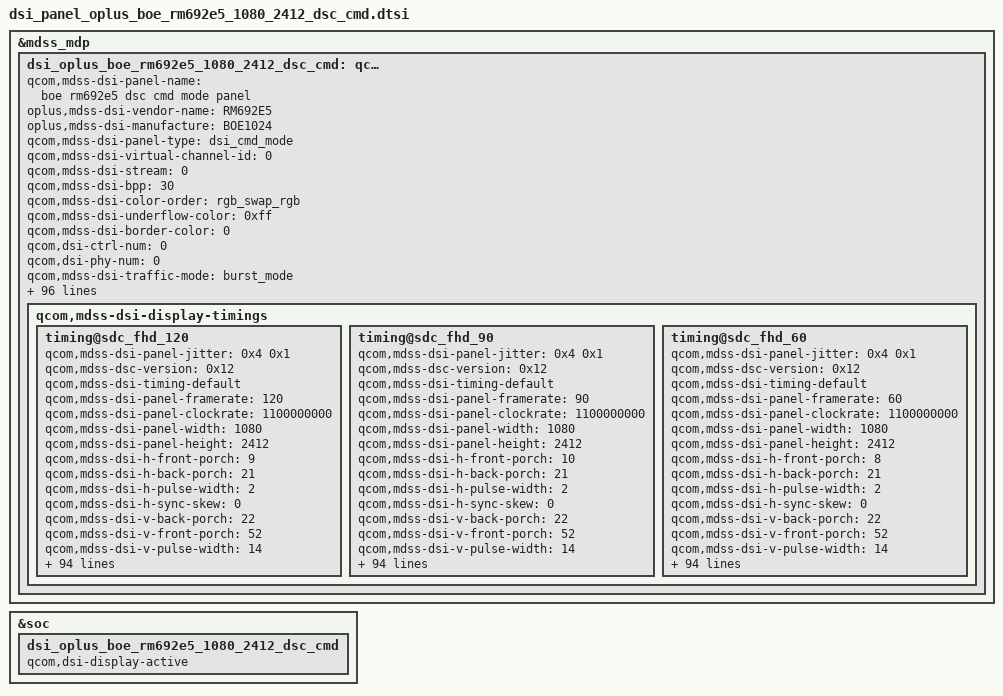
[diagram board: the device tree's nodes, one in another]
&mdss_mdp {
	dsi_oplus_boe_rm692e5_1080_2412_dsc_cmd: qcom,mdss_dsi_oplus_boe_rm692e5_1080_2412_dsc_cmd {
		qcom,mdss-dsi-panel-name = "boe rm692e5 dsc cmd mode panel";
		oplus,mdss-dsi-vendor-name = "RM692E5";
		oplus,mdss-dsi-manufacture = "BOE1024";
		qcom,mdss-dsi-panel-type = "dsi_cmd_mode";
		qcom,mdss-dsi-virtual-channel-id = <0>;
		qcom,mdss-dsi-stream = <0>;
		qcom,mdss-dsi-bpp = <30>;
		qcom,mdss-dsi-color-order = "rgb_swap_rgb";
		qcom,mdss-dsi-underflow-color = <0xff>;
		qcom,mdss-dsi-border-color = <0>;
		qcom,dsi-ctrl-num = <0>;
		qcom,dsi-phy-num = <0>;
		qcom,mdss-dsi-traffic-mode = "burst_mode";
		qcom,mdss-dsi-lane-map = "lane_map_0123";
		qcom,mdss-dsi-bllp-eof-power-mode;
		qcom,mdss-dsi-bllp-power-mode;
		qcom,mdss-dsi-lane-0-state;
		qcom,mdss-dsi-lane-1-state;
		qcom,mdss-dsi-lane-2-state;
		qcom,mdss-dsi-lane-3-state;
		qcom,mdss-dsi-dma-trigger = "trigger_sw";
		qcom,mdss-loading-effect;
		qcom,mdss-dsi-mdp-trigger = "none";
		qcom,mdss-dsi-reset-sequence = <1 10>, <0 5>, <1 32>;
		qcom,mdss-dsi-te-pin-select = <1>;
		qcom,mdss-dsi-te-dcs-command = <1>;
		qcom,mdss-pan-physical-width-dimension = <70>;
		qcom,mdss-pan-physical-height-dimension = <155>;
		qcom,mdss-dsi-init-delay-us = <1000>;
		qcom,mdss-dsi-te-check-enable;
		qcom,mdss-dsi-te-using-te-pin;
		qcom,mdss-dsi-lp11-init;
		qcom,mdss-dsi-wr-mem-start = <0x2c>;
		qcom,mdss-dsi-wr-mem-continue = <0x3c>;
		qcom,mdss-dsi-panel-jitter = <0x4 0x1>;
		//qcom,mdss-dsc-scr-version = <0x1>;
		qcom,mdss-bl-high2bit;
		/* HDR Setting */
		qcom,mdss-dsi-panel-hdr-enabled;
		qcom,mdss-dsi-panel-hdr-color-primaries = <15635 16450 34000 16000 13250 34500 7500 3000>;
		qcom,mdss-dsi-panel-peak-brightness = <5400000>;
		qcom,mdss-dsi-panel-average-brightness = <2000000>;
		qcom,mdss-dsi-panel-blackness-level = <4000>;

		qcom,mdss-dsi-te-using-wd;
		//qcom,esd-check-enabled;
		qcom,mdss-dsi-panel-status-check-mode = "reg_read";
		qcom,mdss-dsi-panel-status-command = [
			06 01 00 00 00 00 02 0B 00
			06 01 00 00 00 00 02 0A 00
			06 01 00 00 00 00 02 FA 00
		];
		qcom,mdss-dsi-panel-status-command-state = "dsi_lp_mode";
		qcom,mdss-dsi-panel-status-value = <0x00 0x9C 0x01>;
		qcom,mdss-dsi-panel-status-read-length = <1 1 1>;
		oplus,mdss-dsi-panel-status-match-modes = <0x00000000>;

		qcom,dynamic-mode-switch-enabled;
		qcom,dynamic-mode-switch-type = "dynamic-resolution-switch-immediate";
		qcom,mdss-dsi-display-timings {
			timing@sdc_fhd_120{
				//qcom,mdss-mdp-transfer-time-us = <12000>;
				qcom,mdss-dsi-panel-jitter = <0x4 0x1>;
				//qcom,mdss-dsc-scr-version = <0x1>;
				qcom,mdss-dsc-version = <0x12>;
				qcom,mdss-dsi-timing-default;
				qcom,mdss-dsi-panel-framerate = <120>;
				qcom,mdss-dsi-panel-clockrate = <1100000000>;
				//qcom,mdss-dsi-panel-clockrate = <900000000>;
				qcom,mdss-dsi-panel-width = <1080>;
				qcom,mdss-dsi-panel-height = <2412>;

				qcom,mdss-dsi-h-front-porch = <9>;
				qcom,mdss-dsi-h-back-porch = <21>;
				qcom,mdss-dsi-h-pulse-width = <2>;
				qcom,mdss-dsi-h-sync-skew = <0>;
				qcom,mdss-dsi-v-back-porch = <22>;
				qcom,mdss-dsi-v-front-porch = <52>;
				qcom,mdss-dsi-v-pulse-width = <14>;
				qcom,mdss-dsi-h-sync-pulse = <0>;

				qcom,mdss-dsi-h-left-border = <0>;
				qcom,mdss-dsi-h-right-border = <0>;
				qcom,mdss-dsi-v-top-border = <0>;
				qcom,mdss-dsi-v-bottom-border = <0>;

				oplus,ofp-aod-off-insert-black = <2>;

				/* Apollo vsync config, need to measure TE signal */
				//oplus,apollo-panel-vsync-width = <13000>;
				//oplus,apollo-panel-vsync-period = <16600>;

				/* ofp config */
				oplus,ofp-need-to-separate-backlight;
				oplus,ofp-hbm-on-period = <2>;

				qcom,mdss-dsi-panel-read-register-open-command = [
					39 01 00 00 00 00 03 F0 5A 5A
					];
				qcom,mdss-dsi-panel-id1-command = [
					06 01 00 00 00 00 01 E9
					];
				qcom,mdss-dsi-panel-read-register-close-command = [
					39 01 00 00 00 00 03 F0 A5 A5
					];
				qcom,mdss-dsi-timing-switch-command = [
					15 01 00 00 00 00 02 FE 40
					15 01 00 00 00 00 02 BD 05
					15 01 00 00 00 00 02 FE 00
					];
				qcom,mdss-dsi-on-command=[
					15 01 00 00 00 00 02 FE F4
					15 01 00 00 00 00 02 00 FF
					15 01 00 00 00 00 02 01 B3
					15 01 00 00 00 00 02 02 CC
					15 01 00 00 00 00 02 03 29
					15 01 00 00 00 00 02 04 74
					15 01 00 00 00 00 02 05 72
					15 01 00 00 00 00 02 06 DD
					15 01 00 00 00 00 02 07 25
					15 01 00 00 00 00 02 08 18
					15 01 00 00 00 00 02 09 61
					15 01 00 00 00 00 02 0A 35
					15 01 00 00 00 00 02 0B 01
					15 01 00 00 00 00 02 0C F4
					15 01 00 00 00 00 02 0D 0C

					15 01 00 00 00 00 02 FE F4
					15 01 00 00 00 00 02 1B F0
					15 01 00 00 00 00 02 1C 7F
					15 01 00 00 00 00 02 1D DE
					15 01 00 00 00 00 02 1E 13
					15 01 00 00 00 00 02 1F 13
					15 01 00 00 00 00 02 20 2A
					15 01 00 00 00 00 02 21 D7
					15 01 00 00 00 00 02 22 5D
					15 01 00 00 00 00 02 23 82
					15 01 00 00 00 00 02 24 11
					15 01 00 00 00 00 02 25 56
					15 01 00 00 00 00 02 26 13
					15 01 00 00 00 00 02 27 40
					15 01 00 00 00 00 02 28 CF
					15 01 00 00 00 00 02 29 00

					15 01 00 00 00 00 02 FE F4
					15 01 00 00 00 00 02 0D C0
					15 01 00 00 00 00 02 0E FF
					15 01 00 00 00 00 02 0F F9
					15 01 00 00 00 00 02 10 0B
					15 01 00 00 00 00 02 11 5E
					15 01 00 00 00 00 02 12 B2
					15 01 00 00 00 00 02 13 5C
					15 01 00 00 00 00 02 14 77
					15 01 00 00 00 00 02 15 09
					15 01 00 00 00 00 02 16 46
					15 01 00 00 00 00 02 17 58
					15 01 00 00 00 00 02 18 4D
					15 01 00 00 00 00 02 19 00
					15 01 00 00 00 00 02 1A 3D
					15 01 00 00 00 00 02 1B 03

					15 01 00 00 00 00 02 FE D2
					15 01 00 00 00 00 02 50 12
					15 01 00 00 00 00 02 51 a0
					15 01 00 00 00 00 02 52 30
					15 01 00 00 00 00 02 53 09
					15 01 00 00 00 00 02 54 6c
					15 01 00 00 00 00 02 55 04
					15 01 00 00 00 00 02 56 38
					15 01 00 00 00 00 02 58 00
					15 01 00 00 00 00 02 59 0c
					15 01 00 00 00 00 02 5a 02
					15 01 00 00 00 00 02 5b 1c
					15 01 00 00 00 00 02 5c 01
					15 01 00 00 00 00 02 5d 9a
					15 01 00 00 00 00 02 5e 19
					15 01 00 00 00 00 02 5f 01
					15 01 00 00 00 00 02 60 03
					15 01 00 00 00 00 02 61 00
					15 01 00 00 00 00 02 62 0a
					15 01 00 00 00 00 02 63 0c
					15 01 00 00 00 00 02 64 08
					15 01 00 00 00 00 02 65 bb
					15 01 00 00 00 00 02 66 0a
					15 01 00 00 00 00 02 67 5f
					15 01 00 00 00 00 02 68 16
					15 01 00 00 00 00 02 69 00
					15 01 00 00 00 00 02 6a 10
					15 01 00 00 00 00 02 6b ec
					15 01 00 00 00 00 02 6c 07
					15 01 00 00 00 00 02 6d 10
					15 01 00 00 00 00 02 6e 20
					15 01 00 00 00 00 02 6f 00
					15 01 00 00 00 00 02 70 06
					15 01 00 00 00 00 02 71 0f
					15 01 00 00 00 00 02 72 0f
					15 01 00 00 00 00 02 73 33
					15 01 00 00 00 00 02 74 0e
					15 01 00 00 00 00 02 75 1c
					15 01 00 00 00 00 02 76 2a
					15 01 00 00 00 00 02 77 38
					15 01 00 00 00 00 02 78 46
					15 01 00 00 00 00 02 79 54
					15 01 00 00 00 00 02 7a 62
					15 01 00 00 00 00 02 7b 69
					15 01 00 00 00 00 02 7c 70
					15 01 00 00 00 00 02 7d 77
					15 01 00 00 00 00 02 7e 79
					15 01 00 00 00 00 02 7f 7b
					15 01 00 00 00 00 02 80 7d
					15 01 00 00 00 00 02 81 7e
					15 01 00 00 00 00 02 82 01
					15 01 00 00 00 00 02 83 c2
					15 01 00 00 00 00 02 84 22
					15 01 00 00 00 00 02 85 00
					15 01 00 00 00 00 02 86 2a
					15 01 00 00 00 00 02 87 40
					15 01 00 00 00 00 02 88 32
					15 01 00 00 00 00 02 89 be
					15 01 00 00 00 00 02 8a 3a
					15 01 00 00 00 00 02 8b fc
					15 01 00 00 00 00 02 8c 3a
					15 01 00 00 00 00 02 8d fa
					15 01 00 00 00 00 02 8e 3a
					15 01 00 00 00 00 02 8f f8
					15 01 00 00 00 00 02 90 3b
					15 01 00 00 00 00 02 91 38
					15 01 00 00 00 00 02 92 3b
					15 01 00 00 00 00 02 93 78
					15 01 00 00 00 00 02 94 3b
					15 01 00 00 00 00 02 95 76
					15 01 00 00 00 00 02 96 4b
					15 01 00 00 00 00 02 97 b6
					15 01 00 00 00 00 02 98 4b
					15 01 00 00 00 00 02 99 b6
					15 01 00 00 00 00 02 9a 4b
					15 01 00 00 00 00 02 9b f4
					15 01 00 00 00 00 02 9c 5b
					15 01 00 00 00 00 02 9d f4
					15 01 00 00 00 00 02 9e 7c
					15 01 00 00 00 00 02 9f 34
					15 01 00 00 00 00 02 a2 02
					15 01 00 00 00 00 02 a3 a3
					15 01 00 00 00 00 02 a4 00
					15 01 00 00 00 00 02 a5 00
					15 01 00 00 00 00 02 a6 00
					15 01 00 00 00 00 02 a7 00
					15 01 00 00 00 00 02 a9 00
					15 01 00 00 00 00 02 aa 00
					15 01 00 00 00 00 02 a0 a0

					15 01 00 00 00 00 02 FE D4
					15 01 00 00 00 00 02 40 03
					15 01 00 00 00 00 02 FE FD
					15 01 00 00 00 00 02 80 06
					15 01 00 00 00 00 02 83 00
					15 01 00 00 00 00 02 FE A0
					15 01 00 00 00 00 02 06 36
					15 01 00 00 00 00 02 FE A1
					15 01 00 00 00 00 02 B3 7F
					15 01 00 00 00 00 02 74 70
					15 01 00 00 00 00 02 FE A1
					15 01 00 00 00 00 02 C3 C3
					15 01 00 00 00 00 02 C4 9C
					15 01 00 00 00 00 02 C5 1E
					15 01 00 00 00 00 02 C6 23

					15 01 00 00 00 00 02 FE 38
					15 01 00 00 00 00 02 18 13
					15 01 00 00 00 00 02 FE 40
					15 01 00 00 00 00 02 BD 05
					15 01 00 00 00 00 02 FE D0
					15 01 00 00 00 00 02 86 14
					15 01 00 00 00 00 02 FE A1
					15 01 00 00 00 00 02 CA 80

					15 01 00 00 00 00 02 FE A1
					15 01 00 00 00 00 02 B3 1F

					/* Setting AOD Black Frames */
					15 01 00 00 00 00 02 FE 40
					15 01 00 00 00 00 02 84 22

					15 01 00 00 00 00 02 FE 00
					15 01 00 00 00 00 02 FA 01
					15 01 00 00 00 00 02 C2 08
					15 01 00 00 00 00 02 35 00

					05 01 00 00 64 00 01 11
					05 01 00 00 0A 00 01 29
				];
				qcom,mdss-dsi-post-on-backlight = [
					/* Display On */
					//05 01 00 00 00 00 02 29 00
				];
				qcom,mdss-dsi-off-command=[
					15 00 00 00 00 00 02 FE 00
					05 00 00 00 0A 00 01 28
					05 00 00 00 64 00 01 10
				];
				qcom,mdss-dsi-lp1-command = [
					/* AOD 50 nit */
					15 00 00 40 00 00 02 FE 74
					15 00 00 40 00 00 02 EC 77
					15 00 00 40 00 00 02 ED 77
					15 00 00 40 00 00 02 EF FF
					15 00 00 40 00 00 02 F0 FF
					15 00 00 40 00 00 02 F2 FF
					15 00 00 00 09 00 02 F3 FF
					/* AOD ON */
					15 00 00 40 00 00 02 FE 40
					15 00 00 40 00 00 02 84 22
					15 00 00 40 00 00 02 B3 50
					15 00 00 40 00 00 02 FE 00
					05 00 00 40 00 00 01 39
					39 00 00 00 11 00 03 51 0F FE
				];
				qcom,mdss-dsi-nolp-command = [
					/* AOD OFF */
					15 00 00 40 00 00 02 FE 40
					15 00 00 40 00 00 02 84 24
					15 00 00 40 00 00 02 B3 4F
					15 00 00 40 00 00 02 FE 00
					05 00 00 00 11 00 01 38
				];
				qcom,mdss-dsi-aod-hbm-on-command = [
					/* AOD OFF */
					15 00 00 40 00 00 02 FE 40
					15 00 00 40 00 00 02 84 22
					15 00 00 40 00 00 02 B3 4F
					15 00 00 40 00 00 02 FE 00
					05 00 00 00 44 00 01 38
					/* HBM ON */
					15 00 00 40 00 00 02 FE 00
					39 00 00 00 00 00 03 51 0F FF
				];
				qcom,mdss-dsi-aod-hbm-off-command = [
					/* HBM OFF */
					15 00 00 40 00 00 02 FE 00
					39 00 00 00 00 00 03 51 00 00
					/* AOD 50 nit */
					15 00 00 40 00 00 02 FE 74
					15 00 00 40 00 00 02 EC 77
					15 00 00 40 00 00 02 ED 77
					15 00 00 40 00 00 02 EF FF
					15 00 00 40 00 00 02 F0 FF
					15 00 00 40 00 00 02 F2 FF
					15 00 00 00 09 00 02 F3 FF
					/* AOD ON */
					15 00 00 40 00 00 02 FE 40
					15 00 00 40 00 00 02 84 22
					15 00 00 40 00 00 02 B3 50
					15 00 00 40 00 00 02 FE 00
					05 00 00 40 00 00 01 39
					39 00 00 00 11 00 03 51 0F FE
				];
				qcom,mdss-dsi-hbm-off-command = [
					15 00 00 00 22 00 02 53 E0
					39 00 00 00 0A 00 03 51 00 4B
				];
				qcom,mdss-dsi-hbm-on-command = [
					/* HBM ON */
					15 00 00 40 00 00 02 FE 00
					39 00 00 00 00 00 03 51 0F FF
				];
				qcom,mdss-dsi-hbm-enter-switch-command = [
					15 01 00 40 00 00 02 FE 00
					39 01 00 00 00 00 03 51 0F FF
				];
				qcom,mdss-dsi-hbm-exit-switch-command = [
					15 01 00 40 00 00 02 FE 00
					39 01 00 00 00 00 03 51 0D BB
				];
				qcom,mdss-dsi-aod-high-mode-command = [
					/* AOD 50 nit */
					15 00 00 40 00 00 02 FE 74
					15 00 00 40 00 00 02 EC 77
					15 00 00 40 00 00 02 ED 77
					15 00 00 40 00 00 02 EF FF
					15 00 00 40 00 00 02 F0 FF
					15 00 00 40 00 00 02 F2 FF
					15 00 00 00 09 00 02 F3 FF
				];
				qcom,mdss-dsi-aod-low-mode-command = [
					/* AOD 10 nit */
					15 00 00 40 00 00 02 FE 74
					15 00 00 40 00 00 02 EC 11
					15 00 00 40 00 00 02 ED 11
					15 00 00 40 00 00 02 EF 98
					15 00 00 40 00 00 02 F0 98
					15 00 00 40 00 00 02 F2 98
					15 00 00 00 09 00 02 F3 98
				];
				qcom,mdss-dsi-esd-switch-page-command = [
					15 01 00 00 00 00 02 FE 00
				];
				qcom,dsi-panel-date-switch-command = [
					15 01 00 00 00 00 02 FE D2
					15 01 00 00 00 00 02 0C 60

					15 01 00 00 00 00 02 FE 88
					15 01 00 00 00 00 02 19 81
					15 01 00 00 00 00 02 18 01
					15 01 00 00 00 00 02 1B 0F
					15 01 00 00 00 00 02 00 A1
					15 01 00 00 00 00 02 02 00
					15 01 00 00 00 00 02 03 C2

					15 01 00 00 00 00 02 FE 00
				];
				qcom,mdss-dsi-ffc-mode0-command = [
					/* CLK=550MHz, OSC=121.9MHz */
					15 00 00 40 00 00 02 FE D4
					15 00 00 40 00 00 02 14 00
					15 00 00 40 00 00 02 FE 40
					15 00 00 40 00 00 02 0A 9F
					15 00 00 40 00 00 02 0B 16
					15 00 00 40 00 00 02 0C 7E
					15 00 00 40 00 00 02 BE 9F
					15 00 00 00 00 00 02 C0 9F
				];
				qcom,mdss-dsi-ffc-mode1-command = [
					/* CLK=550MHz, OSC=121MHz */
					15 00 00 40 00 00 02 FE 40
					15 00 00 40 00 00 02 0A 9C
					15 00 00 40 00 00 02 0B 16
					15 00 00 40 00 00 02 0C 70
					15 00 00 40 00 00 02 BE 9C
					15 00 00 40 00 00 02 C0 9C
					15 00 00 00 00 00 02 16 04

					15 00 00 40 00 00 02 FE D4
					15 00 00 40 00 00 02 14 83
					15 00 00 40 00 00 02 1E 00
					15 00 00 40 00 00 02 1F 16
					15 00 00 40 00 00 02 20 21
					15 00 00 40 00 00 02 21 0C
					15 00 00 40 00 00 02 22 5D
					15 00 00 40 00 00 02 23 0A
					15 00 00 00 00 00 02 24 D1

					15 00 00 40 00 00 02 25 00
					15 00 00 40 00 00 02 26 16
					15 00 00 40 00 00 02 27 21
					15 00 00 40 00 00 02 28 0C
					15 00 00 40 00 00 02 29 5D
					15 00 00 40 00 00 02 2A 0A
					15 00 00 00 00 00 02 2B D1

					15 00 00 40 00 00 02 2D 00
					15 00 00 40 00 00 02 2F 16
					15 00 00 40 00 00 02 30 21
					15 00 00 40 00 00 02 31 0C
					15 00 00 40 00 00 02 32 5D
					15 00 00 40 00 00 02 33 0A
					15 00 00 00 00 00 02 34 D1
				];
				qcom,mdss-dsi-set-backlight-command = [
					15 00 00 40 00 00 02 FE 00
					39 00 00 00 00 00 03 51 06 66
				];
				qcom,mdss-dsi-set-backlight-command-state = "dsi_lp_mode";
				qcom,mdss-dsi-ffc-mode0-command-state = "dsi_lp_mode";
				qcom,mdss-dsi-ffc-mode1-command-state = "dsi_lp_mode";
				qcom,mdss-dsi-aod-hbm-on-command-state = "dsi_lp_mode";
				qcom,mdss-dsi-aod-hbm-off-command-state = "dsi_lp_mode";
				qcom,mdss-dsi-timing-switch-command-state = "dsi_lp_mode";
				qcom,mdss-dsi-on-command-state = "dsi_lp_mode";
				qcom,mdss-dsi-off-command-state = "dsi_lp_mode";
				qcom,mdss-dsi-hbm-on-command-state = "dsi_lp_mode";
				qcom,mdss-dsi-hbm-off-command-state = "dsi_lp_mode";
				qcom,mdss-dsi-nolp-command-state = "dsi_lp_mode";
				qcom,mdss-dsi-lp1-command-state = "dsi_lp_mode";
				qcom,mdss-dsi-aor-restore-command-state = "dsi_lp_mode";
				qcom,dsi-panel-date-switch-command-state = "dsi_lp_mode";

				qcom,lm-split = <540 540>;
				qcom,compression-mode = "dsc";
				qcom,mdss-dsc-encoders = <2>;
				qcom,mdss-dsc-slice-height = <12>;
				qcom,mdss-dsc-slice-width = <540>;
				qcom,mdss-dsc-slice-per-pkt = <1>;
				qcom,mdss-dsc-bit-per-component = <10>;
				qcom,mdss-dsc-bit-per-pixel = <10>;
				qcom,mdss-dsc-block-prediction-enable;
				qcom,mdss-dsi-panel-id1-command-state = "dsi_lp_mode";
				qcom,mdss-dsi-panel-read-register-open-state = "dsi_lp_mode";
				qcom,mdss-dsi-panel-read-register-close-state = "dsi_lp_mode";
			};
			timing@sdc_fhd_90{
				//qcom,mdss-mdp-transfer-time-us = <12000>;
				qcom,mdss-dsi-panel-jitter = <0x4 0x1>;
				//qcom,mdss-dsc-scr-version = <0x1>;
				qcom,mdss-dsc-version = <0x12>;
				qcom,mdss-dsi-timing-default;
				qcom,mdss-dsi-panel-framerate = <90>;
				qcom,mdss-dsi-panel-clockrate = <1100000000>;
				//qcom,mdss-dsi-panel-clockrate = <900000000>;
				qcom,mdss-dsi-panel-width = <1080>;
				qcom,mdss-dsi-panel-height = <2412>;

				qcom,mdss-dsi-h-front-porch = <10>;
				qcom,mdss-dsi-h-back-porch = <21>;
				qcom,mdss-dsi-h-pulse-width = <2>;
				qcom,mdss-dsi-h-sync-skew = <0>;
				qcom,mdss-dsi-v-back-porch = <22>;
				qcom,mdss-dsi-v-front-porch = <52>;
				qcom,mdss-dsi-v-pulse-width = <14>;
				qcom,mdss-dsi-h-sync-pulse = <0>;

				qcom,mdss-dsi-h-left-border = <0>;
				qcom,mdss-dsi-h-right-border = <0>;
				qcom,mdss-dsi-v-top-border = <0>;
				qcom,mdss-dsi-v-bottom-border = <0>;

				oplus,ofp-aod-off-insert-black = <2>;

				/* Apollo vsync config, need to measure TE signal */
				//oplus,apollo-panel-vsync-width = <13000>;
				//oplus,apollo-panel-vsync-period = <16600>;

				/* ofp config */
				oplus,ofp-need-to-separate-backlight;
				oplus,ofp-hbm-on-period = <2>;

				qcom,mdss-dsi-panel-read-register-open-command = [
					39 01 00 00 00 00 03 F0 5A 5A
					];
				qcom,mdss-dsi-panel-id1-command = [
					06 01 00 00 00 00 01 E9
					];
				qcom,mdss-dsi-panel-read-register-close-command = [
					39 01 00 00 00 00 03 F0 A5 A5
					];
				qcom,mdss-dsi-timing-switch-command = [
					15 01 00 00 00 00 02 FE 40
					15 01 00 00 00 00 02 BD 06
					15 01 00 00 00 00 02 FE 00
					];
				qcom,mdss-dsi-on-command=[
					15 01 00 00 00 00 02 FE F4
					15 01 00 00 00 00 02 00 FF
					15 01 00 00 00 00 02 01 B3
					15 01 00 00 00 00 02 02 CC
					15 01 00 00 00 00 02 03 29
					15 01 00 00 00 00 02 04 74
					15 01 00 00 00 00 02 05 72
					15 01 00 00 00 00 02 06 DD
					15 01 00 00 00 00 02 07 25
					15 01 00 00 00 00 02 08 18
					15 01 00 00 00 00 02 09 61
					15 01 00 00 00 00 02 0A 35
					15 01 00 00 00 00 02 0B 01
					15 01 00 00 00 00 02 0C F4
					15 01 00 00 00 00 02 0D 0C

					15 01 00 00 00 00 02 FE F4
					15 01 00 00 00 00 02 1B F0
					15 01 00 00 00 00 02 1C 7F
					15 01 00 00 00 00 02 1D DE
					15 01 00 00 00 00 02 1E 13
					15 01 00 00 00 00 02 1F 13
					15 01 00 00 00 00 02 20 2A
					15 01 00 00 00 00 02 21 D7
					15 01 00 00 00 00 02 22 5D
					15 01 00 00 00 00 02 23 82
					15 01 00 00 00 00 02 24 11
					15 01 00 00 00 00 02 25 56
					15 01 00 00 00 00 02 26 13
					15 01 00 00 00 00 02 27 40
					15 01 00 00 00 00 02 28 CF
					15 01 00 00 00 00 02 29 00

					15 01 00 00 00 00 02 FE F4
					15 01 00 00 00 00 02 0D C0
					15 01 00 00 00 00 02 0E FF
					15 01 00 00 00 00 02 0F F9
					15 01 00 00 00 00 02 10 0B
					15 01 00 00 00 00 02 11 5E
					15 01 00 00 00 00 02 12 B2
					15 01 00 00 00 00 02 13 5C
					15 01 00 00 00 00 02 14 77
					15 01 00 00 00 00 02 15 09
					15 01 00 00 00 00 02 16 46
					15 01 00 00 00 00 02 17 58
					15 01 00 00 00 00 02 18 4D
					15 01 00 00 00 00 02 19 00
					15 01 00 00 00 00 02 1A 3D
					15 01 00 00 00 00 02 1B 03

					15 01 00 00 00 00 02 FE D2
					15 01 00 00 00 00 02 50 12
					15 01 00 00 00 00 02 51 a0
					15 01 00 00 00 00 02 52 30
					15 01 00 00 00 00 02 53 09
					15 01 00 00 00 00 02 54 6c
					15 01 00 00 00 00 02 55 04
					15 01 00 00 00 00 02 56 38
					15 01 00 00 00 00 02 58 00
					15 01 00 00 00 00 02 59 0c
					15 01 00 00 00 00 02 5a 02
					15 01 00 00 00 00 02 5b 1c
					15 01 00 00 00 00 02 5c 01
					15 01 00 00 00 00 02 5d 9a
					15 01 00 00 00 00 02 5e 19
					15 01 00 00 00 00 02 5f 01
					15 01 00 00 00 00 02 60 03
					15 01 00 00 00 00 02 61 00
					15 01 00 00 00 00 02 62 0a
					15 01 00 00 00 00 02 63 0c
					15 01 00 00 00 00 02 64 08
					15 01 00 00 00 00 02 65 bb
					15 01 00 00 00 00 02 66 0a
					15 01 00 00 00 00 02 67 5f
					15 01 00 00 00 00 02 68 16
					15 01 00 00 00 00 02 69 00
					15 01 00 00 00 00 02 6a 10
					15 01 00 00 00 00 02 6b ec
					15 01 00 00 00 00 02 6c 07
					15 01 00 00 00 00 02 6d 10
					15 01 00 00 00 00 02 6e 20
					15 01 00 00 00 00 02 6f 00
					15 01 00 00 00 00 02 70 06
					15 01 00 00 00 00 02 71 0f
					15 01 00 00 00 00 02 72 0f
					15 01 00 00 00 00 02 73 33
					15 01 00 00 00 00 02 74 0e
					15 01 00 00 00 00 02 75 1c
					15 01 00 00 00 00 02 76 2a
					15 01 00 00 00 00 02 77 38
					15 01 00 00 00 00 02 78 46
					15 01 00 00 00 00 02 79 54
					15 01 00 00 00 00 02 7a 62
					15 01 00 00 00 00 02 7b 69
					15 01 00 00 00 00 02 7c 70
					15 01 00 00 00 00 02 7d 77
					15 01 00 00 00 00 02 7e 79
					15 01 00 00 00 00 02 7f 7b
					15 01 00 00 00 00 02 80 7d
					15 01 00 00 00 00 02 81 7e
					15 01 00 00 00 00 02 82 01
					15 01 00 00 00 00 02 83 c2
					15 01 00 00 00 00 02 84 22
					15 01 00 00 00 00 02 85 00
					15 01 00 00 00 00 02 86 2a
					15 01 00 00 00 00 02 87 40
					15 01 00 00 00 00 02 88 32
					15 01 00 00 00 00 02 89 be
					15 01 00 00 00 00 02 8a 3a
					15 01 00 00 00 00 02 8b fc
					15 01 00 00 00 00 02 8c 3a
					15 01 00 00 00 00 02 8d fa
					15 01 00 00 00 00 02 8e 3a
					15 01 00 00 00 00 02 8f f8
					15 01 00 00 00 00 02 90 3b
					15 01 00 00 00 00 02 91 38
					15 01 00 00 00 00 02 92 3b
					15 01 00 00 00 00 02 93 78
					15 01 00 00 00 00 02 94 3b
					15 01 00 00 00 00 02 95 76
					15 01 00 00 00 00 02 96 4b
					15 01 00 00 00 00 02 97 b6
					15 01 00 00 00 00 02 98 4b
					15 01 00 00 00 00 02 99 b6
					15 01 00 00 00 00 02 9a 4b
					15 01 00 00 00 00 02 9b f4
					15 01 00 00 00 00 02 9c 5b
					15 01 00 00 00 00 02 9d f4
					15 01 00 00 00 00 02 9e 7c
					15 01 00 00 00 00 02 9f 34
					15 01 00 00 00 00 02 a2 02
					15 01 00 00 00 00 02 a3 a3
					15 01 00 00 00 00 02 a4 00
					15 01 00 00 00 00 02 a5 00
					15 01 00 00 00 00 02 a6 00
					15 01 00 00 00 00 02 a7 00
					15 01 00 00 00 00 02 a9 00
					15 01 00 00 00 00 02 aa 00
					15 01 00 00 00 00 02 a0 a0

					15 01 00 00 00 00 02 FE D4
					15 01 00 00 00 00 02 40 03
					15 01 00 00 00 00 02 FE FD
					15 01 00 00 00 00 02 80 06
					15 01 00 00 00 00 02 83 00
					15 01 00 00 00 00 02 FE A0
					15 01 00 00 00 00 02 06 36
					15 01 00 00 00 00 02 FE A1
					15 01 00 00 00 00 02 B3 7F
					15 01 00 00 00 00 02 74 70
					15 01 00 00 00 00 02 FE A1
					15 01 00 00 00 00 02 C3 C3
					15 01 00 00 00 00 02 C4 9C
					15 01 00 00 00 00 02 C5 1E
					15 01 00 00 00 00 02 C6 23

					15 01 00 00 00 00 02 FE 38
					15 01 00 00 00 00 02 18 13
					15 01 00 00 00 00 02 FE 40
					15 01 00 00 00 00 02 BD 06
					15 01 00 00 00 00 02 FE D0
					15 01 00 00 00 00 02 86 14
					15 01 00 00 00 00 02 FE A1
					15 01 00 00 00 00 02 CA 80

					15 01 00 00 00 00 02 FE A1
					15 01 00 00 00 00 02 B3 1F

					/* Setting AOD Black Frames */
					15 01 00 00 00 00 02 FE 40
					15 01 00 00 00 00 02 84 22

					15 01 00 00 00 00 02 FE 00
					15 01 00 00 00 00 02 FA 01
					15 01 00 00 00 00 02 C2 08
					15 01 00 00 00 00 02 35 00

					05 01 00 00 64 00 01 11
					05 01 00 00 0A 00 01 29
				];
				qcom,mdss-dsi-post-on-backlight = [
					/* Display On */
					//05 01 00 00 00 00 02 29 00
				];
				qcom,mdss-dsi-off-command=[
					15 00 00 00 00 00 02 FE 00
					05 00 00 00 0A 00 01 28
					05 00 00 00 64 00 01 10
				];
				qcom,mdss-dsi-lp1-command = [
					/* AOD 50 nit */
					15 00 00 40 00 00 02 FE 74
					15 00 00 40 00 00 02 EC 77
					15 00 00 40 00 00 02 ED 77
					15 00 00 40 00 00 02 EF FF
					15 00 00 40 00 00 02 F0 FF
					15 00 00 40 00 00 02 F2 FF
					15 00 00 00 0C 00 02 F3 FF
					/* AOD ON */
					15 00 00 40 00 00 02 FE 40
					15 00 00 40 00 00 02 84 22
					15 00 00 40 00 00 02 B3 50
					15 00 00 40 00 00 02 FE 00
					05 00 00 40 00 00 01 39
					39 00 00 00 17 00 03 51 0F FE
				];
				qcom,mdss-dsi-nolp-command = [
					/* AOD OFF */
					15 00 00 40 00 00 02 FE 40
					15 00 00 40 00 00 02 84 24
					15 00 00 40 00 00 02 B3 4F
					15 00 00 40 00 00 02 FE 00
					05 00 00 00 11 00 01 38
				];
				qcom,mdss-dsi-aod-hbm-on-command = [
					/* AOD OFF */
					15 00 00 40 00 00 02 FE 40
					15 00 00 40 00 00 02 84 22
					15 00 00 40 00 00 02 B3 4F
					15 00 00 40 00 00 02 FE 00
					05 00 00 00 44 00 01 38
					/* HBM ON */
					15 00 00 40 00 00 02 FE 00
					39 00 00 00 00 00 03 51 0F FF
				];
				qcom,mdss-dsi-aod-hbm-off-command = [
					/* HBM OFF */
					15 00 00 40 00 00 02 FE 00
					39 00 00 00 00 00 03 51 00 00
					/* AOD 50 nit */
					15 00 00 40 00 00 02 FE 74
					15 00 00 40 00 00 02 EC 77
					15 00 00 40 00 00 02 ED 77
					15 00 00 40 00 00 02 EF FF
					15 00 00 40 00 00 02 F0 FF
					15 00 00 40 00 00 02 F2 FF
					15 00 00 00 0C 00 02 F3 FF
					/* AOD ON */
					15 00 00 40 00 00 02 FE 40
					15 00 00 40 00 00 02 84 22
					15 00 00 40 00 00 02 B3 50
					15 00 00 40 00 00 02 FE 00
					05 00 00 40 00 00 01 39
					39 00 00 00 17 00 03 51 0F FE
				];
				qcom,mdss-dsi-hbm-off-command = [
					15 00 00 00 22 00 02 53 E0
					39 00 00 00 0A 00 03 51 00 4B
				];
				qcom,mdss-dsi-hbm-on-command = [
					/* HBM ON */
					15 00 00 40 00 00 02 FE 00
					39 00 00 00 00 00 03 51 0F FF
				];
				qcom,mdss-dsi-hbm-enter-switch-command = [
					15 01 00 40 00 00 02 FE 00
					39 01 00 00 00 00 03 51 0F FF
				];
				qcom,mdss-dsi-hbm-exit-switch-command = [
					15 01 00 40 00 00 02 FE 00
					39 01 00 00 00 00 03 51 0D BB
				];
				qcom,mdss-dsi-aod-high-mode-command = [
					/* AOD 50 nit */
					15 00 00 40 00 00 02 FE 74
					15 00 00 40 00 00 02 EC 77
					15 00 00 40 00 00 02 ED 77
					15 00 00 40 00 00 02 EF FF
					15 00 00 40 00 00 02 F0 FF
					15 00 00 40 00 00 02 F2 FF
					15 00 00 00 0C 00 02 F3 FF
				];
				qcom,mdss-dsi-aod-low-mode-command = [
					/* AOD 10 nit */
					15 00 00 40 00 00 02 FE 74
					15 00 00 40 00 00 02 EC 11
					15 00 00 40 00 00 02 ED 11
					15 00 00 40 00 00 02 EF 98
					15 00 00 40 00 00 02 F0 98
					15 00 00 40 00 00 02 F2 98
					15 00 00 00 0C 00 02 F3 98
				];
				qcom,mdss-dsi-esd-switch-page-command = [
					15 01 00 00 00 00 02 FE 00
				];
				qcom,dsi-panel-date-switch-command = [
					15 01 00 00 00 00 02 FE D2
					15 01 00 00 00 00 02 0C 60

					15 01 00 00 00 00 02 FE 88
					15 01 00 00 00 00 02 19 81
					15 01 00 00 00 00 02 18 01
					15 01 00 00 00 00 02 1B 0F
					15 01 00 00 00 00 02 00 A1
					15 01 00 00 00 00 02 02 00
					15 01 00 00 00 00 02 03 C2

					15 01 00 00 00 00 02 FE 00
				];
				qcom,mdss-dsi-ffc-mode0-command = [
					/* CLK=550MHz, OSC=121.9MHz */
					15 00 00 40 00 00 02 FE D4
					15 00 00 40 00 00 02 14 00
					15 00 00 40 00 00 02 FE 40
					15 00 00 40 00 00 02 0A 9F
					15 00 00 40 00 00 02 0B 16
					15 00 00 40 00 00 02 0C 7E
					15 00 00 40 00 00 02 BE 9F
					15 00 00 00 00 00 02 C0 9F
				];
				qcom,mdss-dsi-ffc-mode1-command = [
					/* CLK=550MHz, OSC=121MHz */
					15 00 00 40 00 00 02 FE 40
					15 00 00 40 00 00 02 0A 9C
					15 00 00 40 00 00 02 0B 16
					15 00 00 40 00 00 02 0C 70
					15 00 00 40 00 00 02 BE 9C
					15 00 00 40 00 00 02 C0 9C
					15 00 00 00 00 00 02 16 04

					15 00 00 40 00 00 02 FE D4
					15 00 00 40 00 00 02 14 83
					15 00 00 40 00 00 02 1E 00
					15 00 00 40 00 00 02 1F 16
					15 00 00 40 00 00 02 20 21
					15 00 00 40 00 00 02 21 0C
					15 00 00 40 00 00 02 22 5D
					15 00 00 40 00 00 02 23 0A
					15 00 00 00 00 00 02 24 D1

					15 00 00 40 00 00 02 25 00
					15 00 00 40 00 00 02 26 16
					15 00 00 40 00 00 02 27 21
					15 00 00 40 00 00 02 28 0C
					15 00 00 40 00 00 02 29 5D
					15 00 00 40 00 00 02 2A 0A
					15 00 00 00 00 00 02 2B D1

					15 00 00 40 00 00 02 2D 00
					15 00 00 40 00 00 02 2F 16
					15 00 00 40 00 00 02 30 21
					15 00 00 40 00 00 02 31 0C
					15 00 00 40 00 00 02 32 5D
					15 00 00 40 00 00 02 33 0A
					15 00 00 00 00 00 02 34 D1
				];
				qcom,mdss-dsi-set-backlight-command = [
					15 00 00 40 00 00 02 FE 00
					39 00 00 00 00 00 03 51 06 66
				];
				qcom,mdss-dsi-set-backlight-command-state = "dsi_lp_mode";
				qcom,mdss-dsi-ffc-mode0-command-state = "dsi_lp_mode";
				qcom,mdss-dsi-ffc-mode1-command-state = "dsi_lp_mode";
				qcom,mdss-dsi-aod-hbm-on-command-state = "dsi_lp_mode";
				qcom,mdss-dsi-aod-hbm-off-command-state = "dsi_lp_mode";
				qcom,mdss-dsi-timing-switch-command-state = "dsi_lp_mode";
				qcom,mdss-dsi-on-command-state = "dsi_lp_mode";
				qcom,mdss-dsi-off-command-state = "dsi_lp_mode";
				qcom,mdss-dsi-hbm-on-command-state = "dsi_lp_mode";
				qcom,mdss-dsi-hbm-off-command-state = "dsi_lp_mode";
				qcom,mdss-dsi-nolp-command-state = "dsi_lp_mode";
				qcom,mdss-dsi-lp1-command-state = "dsi_lp_mode";
				qcom,mdss-dsi-aor-restore-command-state = "dsi_lp_mode";
				qcom,dsi-panel-date-switch-command-state = "dsi_lp_mode";

				qcom,lm-split = <540 540>;
				qcom,compression-mode = "dsc";
				qcom,mdss-dsc-encoders = <2>;
				qcom,mdss-dsc-slice-height = <12>;
				qcom,mdss-dsc-slice-width = <540>;
				qcom,mdss-dsc-slice-per-pkt = <1>;
				qcom,mdss-dsc-bit-per-component = <10>;
				qcom,mdss-dsc-bit-per-pixel = <10>;
				qcom,mdss-dsc-block-prediction-enable;
				qcom,mdss-dsi-panel-id1-command-state = "dsi_lp_mode";
				qcom,mdss-dsi-panel-read-register-open-state = "dsi_lp_mode";
				qcom,mdss-dsi-panel-read-register-close-state = "dsi_lp_mode";
			};
			timing@sdc_fhd_60{
				//qcom,mdss-mdp-transfer-time-us = <12000>;
				qcom,mdss-dsi-panel-jitter = <0x4 0x1>;
				//qcom,mdss-dsc-scr-version = <0x1>;
				qcom,mdss-dsc-version = <0x12>;
				qcom,mdss-dsi-timing-default;
				qcom,mdss-dsi-panel-framerate = <60>;
				qcom,mdss-dsi-panel-clockrate = <1100000000>;
				//qcom,mdss-dsi-panel-clockrate = <900000000>;
				qcom,mdss-dsi-panel-width = <1080>;
				qcom,mdss-dsi-panel-height = <2412>;

				qcom,mdss-dsi-h-front-porch = <8>;
				qcom,mdss-dsi-h-back-porch = <21>;
				qcom,mdss-dsi-h-pulse-width = <2>;
				qcom,mdss-dsi-h-sync-skew = <0>;
				qcom,mdss-dsi-v-back-porch = <22>;
				qcom,mdss-dsi-v-front-porch = <52>;
				qcom,mdss-dsi-v-pulse-width = <14>;
				qcom,mdss-dsi-h-sync-pulse = <0>;

				qcom,mdss-dsi-h-left-border = <0>;
				qcom,mdss-dsi-h-right-border = <0>;
				qcom,mdss-dsi-v-top-border = <0>;
				qcom,mdss-dsi-v-bottom-border = <0>;

				oplus,ofp-aod-off-insert-black = <2>;

				/* Apollo vsync config, need to measure TE signal */
				//oplus,apollo-panel-vsync-width = <13000>;
				//oplus,apollo-panel-vsync-period = <16600>;

				/* ofp config */
				oplus,ofp-need-to-separate-backlight;
				oplus,ofp-hbm-on-period = <2>;

				qcom,mdss-dsi-panel-read-register-open-command = [
					39 01 00 00 00 00 03 F0 5A 5A
					];
				qcom,mdss-dsi-panel-id1-command = [
					06 01 00 00 00 00 01 E9
					];
				qcom,mdss-dsi-panel-read-register-close-command = [
					39 01 00 00 00 00 03 F0 A5 A5
					];
				qcom,mdss-dsi-timing-switch-command = [
					15 01 00 00 00 00 02 FE 40
					15 01 00 00 00 00 02 BD 00
					15 01 00 00 00 00 02 FE 00
					];
				qcom,mdss-dsi-on-command=[
					15 01 00 00 00 00 02 FE F4
					15 01 00 00 00 00 02 00 FF
					15 01 00 00 00 00 02 01 B3
					15 01 00 00 00 00 02 02 CC
					15 01 00 00 00 00 02 03 29
					15 01 00 00 00 00 02 04 74
					15 01 00 00 00 00 02 05 72
					15 01 00 00 00 00 02 06 DD
					15 01 00 00 00 00 02 07 25
					15 01 00 00 00 00 02 08 18
					15 01 00 00 00 00 02 09 61
					15 01 00 00 00 00 02 0A 35
					15 01 00 00 00 00 02 0B 01
					15 01 00 00 00 00 02 0C F4
					15 01 00 00 00 00 02 0D 0C

					15 01 00 00 00 00 02 FE F4
					15 01 00 00 00 00 02 1B F0
					15 01 00 00 00 00 02 1C 7F
					15 01 00 00 00 00 02 1D DE
					15 01 00 00 00 00 02 1E 13
					15 01 00 00 00 00 02 1F 13
					15 01 00 00 00 00 02 20 2A
					15 01 00 00 00 00 02 21 D7
					15 01 00 00 00 00 02 22 5D
					15 01 00 00 00 00 02 23 82
					15 01 00 00 00 00 02 24 11
					15 01 00 00 00 00 02 25 56
					15 01 00 00 00 00 02 26 13
					15 01 00 00 00 00 02 27 40
					15 01 00 00 00 00 02 28 CF
					15 01 00 00 00 00 02 29 00

					15 01 00 00 00 00 02 FE F4
					15 01 00 00 00 00 02 0D C0
					15 01 00 00 00 00 02 0E FF
					15 01 00 00 00 00 02 0F F9
					15 01 00 00 00 00 02 10 0B
					15 01 00 00 00 00 02 11 5E
					15 01 00 00 00 00 02 12 B2
					15 01 00 00 00 00 02 13 5C
					15 01 00 00 00 00 02 14 77
					15 01 00 00 00 00 02 15 09
					15 01 00 00 00 00 02 16 46
					15 01 00 00 00 00 02 17 58
					15 01 00 00 00 00 02 18 4D
					15 01 00 00 00 00 02 19 00
					15 01 00 00 00 00 02 1A 3D
					15 01 00 00 00 00 02 1B 03

					15 01 00 00 00 00 02 FE D2
					15 01 00 00 00 00 02 50 12
					15 01 00 00 00 00 02 51 a0
					15 01 00 00 00 00 02 52 30
					15 01 00 00 00 00 02 53 09
					15 01 00 00 00 00 02 54 6c
					15 01 00 00 00 00 02 55 04
					15 01 00 00 00 00 02 56 38
					15 01 00 00 00 00 02 58 00
					15 01 00 00 00 00 02 59 0c
					15 01 00 00 00 00 02 5a 02
					15 01 00 00 00 00 02 5b 1c
					15 01 00 00 00 00 02 5c 01
					15 01 00 00 00 00 02 5d 9a
					15 01 00 00 00 00 02 5e 19
					15 01 00 00 00 00 02 5f 01
					15 01 00 00 00 00 02 60 03
					15 01 00 00 00 00 02 61 00
					15 01 00 00 00 00 02 62 0a
					15 01 00 00 00 00 02 63 0c
					15 01 00 00 00 00 02 64 08
					15 01 00 00 00 00 02 65 bb
					15 01 00 00 00 00 02 66 0a
					15 01 00 00 00 00 02 67 5f
					15 01 00 00 00 00 02 68 16
					15 01 00 00 00 00 02 69 00
					15 01 00 00 00 00 02 6a 10
					15 01 00 00 00 00 02 6b ec
					15 01 00 00 00 00 02 6c 07
					15 01 00 00 00 00 02 6d 10
					15 01 00 00 00 00 02 6e 20
					15 01 00 00 00 00 02 6f 00
					15 01 00 00 00 00 02 70 06
					15 01 00 00 00 00 02 71 0f
					15 01 00 00 00 00 02 72 0f
					15 01 00 00 00 00 02 73 33
					15 01 00 00 00 00 02 74 0e
					15 01 00 00 00 00 02 75 1c
					15 01 00 00 00 00 02 76 2a
					15 01 00 00 00 00 02 77 38
					15 01 00 00 00 00 02 78 46
					15 01 00 00 00 00 02 79 54
					15 01 00 00 00 00 02 7a 62
					15 01 00 00 00 00 02 7b 69
					15 01 00 00 00 00 02 7c 70
					15 01 00 00 00 00 02 7d 77
					15 01 00 00 00 00 02 7e 79
					15 01 00 00 00 00 02 7f 7b
					15 01 00 00 00 00 02 80 7d
					15 01 00 00 00 00 02 81 7e
					15 01 00 00 00 00 02 82 01
					15 01 00 00 00 00 02 83 c2
					15 01 00 00 00 00 02 84 22
					15 01 00 00 00 00 02 85 00
					15 01 00 00 00 00 02 86 2a
					15 01 00 00 00 00 02 87 40
					15 01 00 00 00 00 02 88 32
					15 01 00 00 00 00 02 89 be
					15 01 00 00 00 00 02 8a 3a
					15 01 00 00 00 00 02 8b fc
					15 01 00 00 00 00 02 8c 3a
					15 01 00 00 00 00 02 8d fa
					15 01 00 00 00 00 02 8e 3a
					15 01 00 00 00 00 02 8f f8
					15 01 00 00 00 00 02 90 3b
					15 01 00 00 00 00 02 91 38
					15 01 00 00 00 00 02 92 3b
					15 01 00 00 00 00 02 93 78
					15 01 00 00 00 00 02 94 3b
					15 01 00 00 00 00 02 95 76
					15 01 00 00 00 00 02 96 4b
					15 01 00 00 00 00 02 97 b6
					15 01 00 00 00 00 02 98 4b
					15 01 00 00 00 00 02 99 b6
					15 01 00 00 00 00 02 9a 4b
					15 01 00 00 00 00 02 9b f4
					15 01 00 00 00 00 02 9c 5b
					15 01 00 00 00 00 02 9d f4
					15 01 00 00 00 00 02 9e 7c
					15 01 00 00 00 00 02 9f 34
					15 01 00 00 00 00 02 a2 02
					15 01 00 00 00 00 02 a3 a3
					15 01 00 00 00 00 02 a4 00
					15 01 00 00 00 00 02 a5 00
					15 01 00 00 00 00 02 a6 00
					15 01 00 00 00 00 02 a7 00
					15 01 00 00 00 00 02 a9 00
					15 01 00 00 00 00 02 aa 00
					15 01 00 00 00 00 02 a0 a0

					15 01 00 00 00 00 02 FE D4
					15 01 00 00 00 00 02 40 03
					15 01 00 00 00 00 02 FE FD
					15 01 00 00 00 00 02 80 06
					15 01 00 00 00 00 02 83 00
					15 01 00 00 00 00 02 FE A0
					15 01 00 00 00 00 02 06 36
					15 01 00 00 00 00 02 FE A1
					15 01 00 00 00 00 02 B3 7F
					15 01 00 00 00 00 02 74 70
					15 01 00 00 00 00 02 FE A1
					15 01 00 00 00 00 02 C3 C3
					15 01 00 00 00 00 02 C4 9C
					15 01 00 00 00 00 02 C5 1E
					15 01 00 00 00 00 02 C6 23

					15 01 00 00 00 00 02 FE 38
					15 01 00 00 00 00 02 18 13
					15 01 00 00 00 00 02 FE 40
					15 01 00 00 00 00 02 BD 00
					15 01 00 00 00 00 02 FE D0
					15 01 00 00 00 00 02 86 14
					15 01 00 00 00 00 02 FE A1
					15 01 00 00 00 00 02 CA 80

					15 01 00 00 00 00 02 FE A1
					15 01 00 00 00 00 02 B3 1F

					/* Setting AOD Black Frames */
					15 01 00 00 00 00 02 FE 40
					15 01 00 00 00 00 02 84 22

					15 01 00 00 00 00 02 FE 00
					15 01 00 00 00 00 02 FA 01
					15 01 00 00 00 00 02 C2 08
					15 01 00 00 00 00 02 35 00

					05 01 00 00 64 00 01 11
					05 01 00 00 0A 00 01 29
				];
				qcom,mdss-dsi-post-on-backlight = [
					/* Display On */
					//05 01 00 00 00 00 02 29 00
				];
				qcom,mdss-dsi-off-command=[
					15 00 00 00 00 00 02 FE 00
					05 00 00 00 0A 00 01 28
					05 00 00 00 64 00 01 10
				];
				qcom,mdss-dsi-lp1-command = [
					/* AOD 50 nit */
					15 00 00 40 00 00 02 FE 74
					15 00 00 40 00 00 02 EC 77
					15 00 00 40 00 00 02 ED 77
					15 00 00 40 00 00 02 EF FF
					15 00 00 40 00 00 02 F0 FF
					15 00 00 40 00 00 02 F2 FF
					15 00 00 00 11 00 02 F3 FF
					/* AOD ON */
					15 00 00 40 00 00 02 FE 40
					15 00 00 40 00 00 02 84 22
					15 00 00 40 00 00 02 B3 50
					15 00 00 40 00 00 02 FE 00
					05 00 00 40 00 00 01 39
					39 00 00 00 22 00 03 51 0F FE
				];
				qcom,mdss-dsi-nolp-command = [
					/* AOD OFF */
					15 00 00 40 00 00 02 FE 40
					15 00 00 40 00 00 02 84 24
					15 00 00 40 00 00 02 B3 4F
					15 00 00 40 00 00 02 FE 00
					05 00 00 00 11 00 01 38
				];
				qcom,mdss-dsi-aod-hbm-on-command = [
					/* AOD OFF */
					15 00 00 40 00 00 02 FE 40
					15 00 00 40 00 00 02 84 22
					15 00 00 40 00 00 02 B3 4F
					15 00 00 40 00 00 02 FE 00
					05 00 00 00 44 00 01 38
					/* HBM ON */
					15 00 00 40 00 00 02 FE 00
					39 00 00 00 00 00 03 51 0F FF
				];
				qcom,mdss-dsi-aod-hbm-off-command = [
					/* HBM OFF */
					15 00 00 40 00 00 02 FE 00
					39 00 00 00 00 00 03 51 00 00
					/* AOD 50 nit */
					15 00 00 40 00 00 02 FE 74
					15 00 00 40 00 00 02 EC 77
					15 00 00 40 00 00 02 ED 77
					15 00 00 40 00 00 02 EF FF
					15 00 00 40 00 00 02 F0 FF
					15 00 00 40 00 00 02 F2 FF
					15 00 00 00 11 00 02 F3 FF
					/* AOD ON */
					15 00 00 40 00 00 02 FE 40
					15 00 00 40 00 00 02 84 22
					15 00 00 40 00 00 02 B3 50
					15 00 00 40 00 00 02 FE 00
					05 00 00 40 00 00 01 39
					39 00 00 00 22 00 03 51 0F FE
				];
				qcom,mdss-dsi-hbm-off-command = [
					15 00 00 00 22 00 02 53 E0
					39 00 00 00 0A 00 03 51 00 4B
				];
				qcom,mdss-dsi-hbm-on-command = [
					/* HBM ON */
					15 00 00 40 00 00 02 FE 00
					39 00 00 00 00 00 03 51 0F FF
				];
				qcom,mdss-dsi-hbm-enter-switch-command = [
					15 01 00 40 00 00 02 FE 00
					39 01 00 00 00 00 03 51 0F FF
				];
				qcom,mdss-dsi-hbm-exit-switch-command = [
					15 01 00 40 00 00 02 FE 00
					39 01 00 00 00 00 03 51 0D BB
				];
				qcom,mdss-dsi-aod-high-mode-command = [
					/* AOD 50 nit */
					15 00 00 40 00 00 02 FE 74
					15 00 00 40 00 00 02 EC 77
					15 00 00 40 00 00 02 ED 77
					15 00 00 40 00 00 02 EF FF
					15 00 00 40 00 00 02 F0 FF
					15 00 00 40 00 00 02 F2 FF
					15 00 00 00 11 00 02 F3 FF
				];
				qcom,mdss-dsi-aod-low-mode-command = [
					/* AOD 10 nit */
					15 00 00 40 00 00 02 FE 74
					15 00 00 40 00 00 02 EC 11
					15 00 00 40 00 00 02 ED 11
					15 00 00 40 00 00 02 EF 98
					15 00 00 40 00 00 02 F0 98
					15 00 00 40 00 00 02 F2 98
					15 00 00 00 11 00 02 F3 98
				];
				qcom,mdss-dsi-esd-switch-page-command = [
					15 01 00 00 00 00 02 FE 00
				];
				qcom,dsi-panel-date-switch-command = [
					15 01 00 00 00 00 02 FE D2
					15 01 00 00 00 00 02 0C 60

					15 01 00 00 00 00 02 FE 88
					15 01 00 00 00 00 02 19 81
					15 01 00 00 00 00 02 18 01
					15 01 00 00 00 00 02 1B 0F
					15 01 00 00 00 00 02 00 A1
					15 01 00 00 00 00 02 02 00
					15 01 00 00 00 00 02 03 C2

					15 01 00 00 00 00 02 FE 00
				];
				qcom,mdss-dsi-ffc-mode0-command = [
					/* CLK=550MHz, OSC=121.9MHz */
					15 00 00 40 00 00 02 FE D4
					15 00 00 40 00 00 02 14 00
					15 00 00 40 00 00 02 FE 40
					15 00 00 40 00 00 02 0A 9F
					15 00 00 40 00 00 02 0B 16
					15 00 00 40 00 00 02 0C 7E
					15 00 00 40 00 00 02 BE 9F
					15 00 00 00 00 00 02 C0 9F
				];
				qcom,mdss-dsi-ffc-mode1-command = [
					/* CLK=550MHz, OSC=121MHz */
					15 00 00 40 00 00 02 FE 40
					15 00 00 40 00 00 02 0A 9C
					15 00 00 40 00 00 02 0B 16
					15 00 00 40 00 00 02 0C 70
					15 00 00 40 00 00 02 BE 9C
					15 00 00 40 00 00 02 C0 9C
					15 00 00 00 00 00 02 16 04

					15 00 00 40 00 00 02 FE D4
					15 00 00 40 00 00 02 14 83
					15 00 00 40 00 00 02 1E 00
					15 00 00 40 00 00 02 1F 16
					15 00 00 40 00 00 02 20 21
					15 00 00 40 00 00 02 21 0C
					15 00 00 40 00 00 02 22 5D
					15 00 00 40 00 00 02 23 0A
					15 00 00 00 00 00 02 24 D1

					15 00 00 40 00 00 02 25 00
					15 00 00 40 00 00 02 26 16
					15 00 00 40 00 00 02 27 21
					15 00 00 40 00 00 02 28 0C
					15 00 00 40 00 00 02 29 5D
					15 00 00 40 00 00 02 2A 0A
					15 00 00 00 00 00 02 2B D1

					15 00 00 40 00 00 02 2D 00
					15 00 00 40 00 00 02 2F 16
					15 00 00 40 00 00 02 30 21
					15 00 00 40 00 00 02 31 0C
					15 00 00 40 00 00 02 32 5D
					15 00 00 40 00 00 02 33 0A
					15 00 00 00 00 00 02 34 D1
				];
				qcom,mdss-dsi-set-backlight-command = [
					15 00 00 40 00 00 02 FE 00
					39 00 00 00 00 00 03 51 06 66
				];
				qcom,mdss-dsi-set-backlight-command-state = "dsi_lp_mode";
				qcom,mdss-dsi-ffc-mode0-command-state = "dsi_lp_mode";
				qcom,mdss-dsi-ffc-mode1-command-state = "dsi_lp_mode";
				qcom,mdss-dsi-aod-hbm-on-command-state = "dsi_lp_mode";
				qcom,mdss-dsi-aod-hbm-off-command-state = "dsi_lp_mode";
				qcom,mdss-dsi-timing-switch-command-state = "dsi_lp_mode";
				qcom,mdss-dsi-on-command-state = "dsi_lp_mode";
				qcom,mdss-dsi-off-command-state = "dsi_lp_mode";
				qcom,mdss-dsi-hbm-on-command-state = "dsi_lp_mode";
				qcom,mdss-dsi-hbm-off-command-state = "dsi_lp_mode";
				qcom,mdss-dsi-nolp-command-state = "dsi_lp_mode";
				qcom,mdss-dsi-lp1-command-state = "dsi_lp_mode";
				qcom,mdss-dsi-aor-restore-command-state = "dsi_lp_mode";
				qcom,dsi-panel-date-switch-command-state = "dsi_lp_mode";

				qcom,lm-split = <540 540>;
				qcom,compression-mode = "dsc";
				qcom,mdss-dsc-encoders = <2>;
				qcom,mdss-dsc-slice-height = <12>;
				qcom,mdss-dsc-slice-width = <540>;
				qcom,mdss-dsc-slice-per-pkt = <1>;
				qcom,mdss-dsc-bit-per-component = <10>;
				qcom,mdss-dsc-bit-per-pixel = <10>;
				qcom,mdss-dsc-block-prediction-enable;
				qcom,mdss-dsi-panel-id1-command-state = "dsi_lp_mode";
				qcom,mdss-dsi-panel-read-register-open-state = "dsi_lp_mode";
				qcom,mdss-dsi-panel-read-register-close-state = "dsi_lp_mode";
			};
		};
	};
};

&soc {
	dsi_oplus_boe_rm692e5_1080_2412_dsc_cmd {
		qcom,dsi-display-active;
	};
};

&dsi_oplus_boe_rm692e5_1080_2412_dsc_cmd {
	qcom,panel-supply-entries = <&oplus_zonda_dsi_panel_pwr_supply>;
	qcom,mdss-dsi-panel-controller = <&mdss_dsi0>;
	qcom,bl-update-flag = "delay_until_first_frame";
	qcom,mdss-dsi-bl-pmic-control-type = "bl_ctrl_dcs";
	qcom,bl-dsc-cmd-state = "dsi_lp_mode";
	qcom,mdss-dsi-bl-inverted-dbv;
	qcom,mdss-dsi-bl-min-level = <1>;
	qcom,mdss-dsi-bl-max-level = <4095>;
	qcom,mdss-brightness-max-level = <4095>;
	oplus,dsi-brightness-normal-max-level = <3515>;
	oplus,dsi-bl-normal-max-level = <3515>;
	oplus,dsi-brightness-default-level = <1638>;
	oplus,dsi-dc-backlight-threshold = <1960>;
	qcom,platform-te-gpio = <&tlmm 86 0>;
	qcom,platform-reset-gpio = <&tlmm 3 0>;
	qcom,platform-panel-vout-gpio = <&tlmm 90 0>;
	qcom,platform-panel-vddr-aod-en-gpio = <&tlmm 180 0>;

	qcom,ulps-enabled;
	qcom,dsi-select-clocks = "pll_byte_clk0", "pll_dsi_clk0";

	/* OFP CONFIG */
	oplus,ofp-fp-type = <0x08>;

	/* osc features config */
	//oplus,ffc-enabled;
	oplus,clk-osc-sequence =
		<1100000000 121900>,
		<1100000000 121000>;

	/* oplus features config */
	oplus,dsi-serial-number-enabled;
	oplus,dsi-serial-number-reg= <0xA1>;
	oplus,dsi-serial-number-index= <8>;
	oplus,dsi-serial-number-read-count= <15>;
	oplus,ofp-config = <01>;
	oplus,dsi-ofp-brightness = <36 0xed>,
			<60 0xec>,
			<90 0xeb>,
			<140 0xea>,
			<200 0xe8>,
			<300 0xe4>,
			<458 0xe0>,
			<605 0xdb>,
			<743 0xcf>,
			<912 0xc8>,
			<1062 0xbf>,
			<1187 0xb6>,
			<1393 0xa0>,
			<1611 0x9b>,
			<1787 0x92>,
			<2000 0x8b>,
			<2200 0x80>,
			<2400 0x70>,
			<2600 0x60>,
			<2800 0x50>,
			<3000 0x4A>,
			<3200 0x40>,
			<3400 0x36>,
			<3515 0x2e>;
	oplus,dsi-dc-brightness = <0 0xff>,
			<2 0xFC>,
			<4 0xF9>,
			<6 0xF9>,
			<8 0xF8>,
			<10 0xF7>,
			<15 0xF6>,
			<20 0xF4>,
			<30 0xF0>,
			<40 0xEB>,
			<50 0xE6>,
			<60 0xE1>,
			<70 0xDD>,
			<80 0xD8>,
			<100 0xCF>,
			<120 0xC5>,
			<150 0xB9>,
			<200 0xA2>,
			<250 0x8C>,
			<300 0x76>,
			<350 0x5B>,
			<400 0x44>,
			<450 0x2C>,
			<500 0x0D>,
			<520 0x00>;


	qcom,mdss-dsi-display-timings {
		timing@sdc_fhd_120 { /* FHD+ 120hz 550Mhz 1100Mbps */
			qcom,mdss-dsi-panel-phy-timings = [00 24 0A 0A 1A 25 09 0A 09 02 04 00 1E 0F];
			//qcom,mdss-dsi-panel-phy-timings = [00 1E 08 07 18 16 08 08 08 02 04 00 1A 0C];// 450M
			qcom,display-topology = <1 1 1>,<2 2 1>;
			qcom,default-topology-index = <1>;
		};
		timing@sdc_fhd_90 { /* FHD+ 120hz 550Mhz 1100Mbps */
			qcom,mdss-dsi-panel-phy-timings = [00 24 0A 0A 1A 25 09 0A 09 02 04 00 1E 0F];
			//qcom,mdss-dsi-panel-phy-timings = [00 1E 08 07 18 16 08 08 08 02 04 00 1A 0C];// 450M
			qcom,display-topology = <1 1 1>,<2 2 1>;
			qcom,default-topology-index = <1>;
		};
		timing@sdc_fhd_60 { /* FHD+ 120hz 550Mhz 1100Mbps */
			qcom,mdss-dsi-panel-phy-timings = [00 24 0A 0A 1A 25 09 0A 09 02 04 00 1E 0F];
			//qcom,mdss-dsi-panel-phy-timings = [00 1E 08 07 18 16 08 08 08 02 04 00 1A 0C];// 450M
			qcom,display-topology = <1 1 1>,<2 2 1>;
			qcom,default-topology-index = <1>;
		};
	};
};
&dsi_oplus_boe_rm692e5_1080_2412_dsc_cmd {
	qcom,panel_voltage_vddi_name = "vddio";
	qcom,panel_voltage_vddi = <0 1800000 1850000 1950000>;
	qcom,panel_voltage_vddr_name = "vddio";
	qcom,panel_voltage_vddr = <1 1800000 1850000 1950000>;
};

&dsi_oplus_boe_rm692e5_1080_2412_dsc_cmd {
	oplus,color_dual_brightness_status;
};

